# PIC32CK2051SG00144 device description
Architecture: CORTEX-M33; Family: PIC32CK; Series: PIC32CKSG00
Registers are 32-bit, read-write, reset 0x0 unless marked. A register's access mark holds for its fields unless they carry their own. Offsets are from the block's base; [hi:lo] are bit positions; {n}, {i} and the like mark numbered series; 'fields as' and 'values as' point back to an identical list.

## FUSES_BOOTCFG1 — Defines FUSE parameters
Instances: FUSES_BOOTCFG1 0x0A002000, FUSES_BOOTCFG2 0x0A00A000
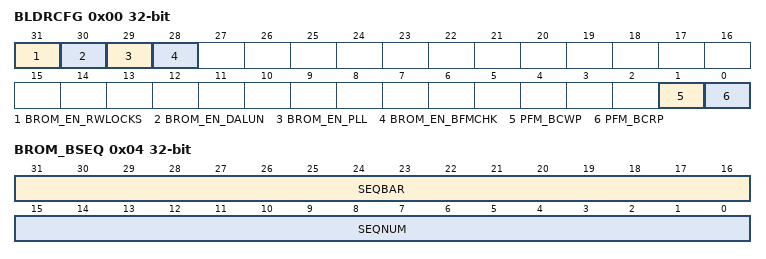
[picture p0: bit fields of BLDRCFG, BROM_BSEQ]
0x00 BLDRCFG reset not defined — Bootloader Configuration
  [31] BROM_EN_RWLOCKS — Enable Read/Write Locks
  [30] BROM_EN_DALUN — Enable DAL Unlock
  [29] BROM_EN_PLL — Enable PLL (Settings in PLL0_<REGS> are used)
  [28] BROM_EN_BFMCHK — Enable BFM CRC Check
    0=NONE (No verification); 1=CRC32 (Verify using crc32)
  [1] PFM_BCWP — Boot Configration Page Write Protect
  [0] PFM_BCRP — Boot Configration Page Read Protect
0x04 BROM_BSEQ reset not defined — Boot Configuraiton Page Sequence Number
  [31:16] SEQBAR — Sequence Number Bar (Negeated)
  [15:0] SEQNUM — Sequence Number
0x08 BFM_CHK_TABLEPTR reset not defined — BFM CRC Table Pointer
{0x20+4i} KEYVAL_TZ1_CE_NS[{i}] (i=0..3) reset not defined — Chip Erase Key for TZ1_NS
{0x30+4i} CELOCK_TZ1_CE_NS[{i}] (i=0..3) reset not defined — Chip Erase Lock for TZ1_NS
{0x40+4i} KEYVAL_TZ1_CE_S[{i}] (i=0..3) reset not defined — Chip Erase Key for TZ1_S
{0x50+4i} CELOCK_TZ1_CE_S[{i}] (i=0..3) reset not defined — Chip Erase Lock for TZ1_S
{0x60+4i} KEYVAL_TZ1_CE_ALL[{i}] (i=0..3) reset not defined — Chip Erase Key for TZ1_ALL
{0x70+4i} CELOCK_TZ1_CE_ALL[{i}] (i=0..3) reset not defined — Chip Erase Lock for TZ1_ALL
{0x80+4i} KEYVAL_TZ0_CE_ALL[{i}] (i=0..3) reset not defined — Chip Erase Key for TZ0_ALL
{0x90+4i} CELOCK_TZ0_CE_ALL[{i}] (i=0..3) reset not defined — Chip Erase Lock for TZ0_ALL
{0xA0+4i} KEYVAL_CRCCMD[{i}] (i=0..3) reset not defined — CRC Access Key
{0xB0+4i} KEYCONFIG_CRCCMD[{i}] (i=0..3) reset not defined — CRC Access Key Configuration
{0xC0+4i} KEYVAL_HOSTDALELEV[{i}] (i=0..3) reset not defined — Host Authenticated DAL Elevation Key
{0xD0+4i} KEYCONFIG_HOSTDALELEV[{i}] (i=0..3) reset not defined — Host Authenticated DAL Elevation Key Configuration
0xE0 ROM_CTRLA reset not defined — ROM CTRLA Settings (BROM_PLLEN must be set)
0xE4 FCR_CTRLA reset not defined — FCR CTRLA Settings (BROM_PLLEN must be set)
0xE8 RPMU_VREGCTRL reset not defined — RPMU VREGCTRL Settings (BROM_PLLEN must be set)
0xEC PLL0_CTRL reset not defined — PLL0 CTRL Settings (BROM_PLLEN must be set)
0xF0 PLL0_FBDIV reset not defined — PLL0 FBDIV Settings (BROM_PLLEN must be set)
0xF4 PLL0_REFDIV reset not defined — PLL0 REFDIV Settings (BROM_PLLEN must be set)
0xF8 PLL0_POSTDIVA reset not defined — PLL0 POSTDIVA Settings (BROM_PLLEN must be set)
0xFC MCLK_CLKDIV1 reset not defined — MCLK CLKDIV1 Settings (BROM_PLLEN must be set)
0x100 GCLK_GENCTRL0 reset not defined — GCLK GENCTRL0 Settings (BROM_PLLEN must be set)
{0x110+4i} BROM_BOOTCFGCRC[{i}] (i=0..3) reset not defined — Boot Configuraiton Page CRC
0x120 BROM_PAGEEND reset not defined — Page End Marker for Verified Data

## FUSES_DALCFG — Defines FUSE parameters
Instances: FUSES_DALCFG 0x0A004000
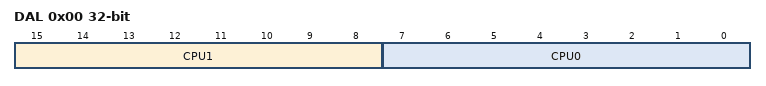
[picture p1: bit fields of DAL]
0x00 DAL — Debug Access Level
  [15:8] CPU1 — HSM DAL Elevation Value
    129=DAL0 (FCW_DAL0_VALUE); 153=DAL1 (FCW_DAL1_VALUE); 219=DAL2 (FCW_DAL2_VALUE)
  [7:0] CPU0 — Host DAL Elevation Value
    values as CPU1

## FUSES_USERCFG1 — Defines FUSE parameters
Instances: FUSES_USERCFG1 0x0A000000, FUSES_USERCFG2 0x0A008000
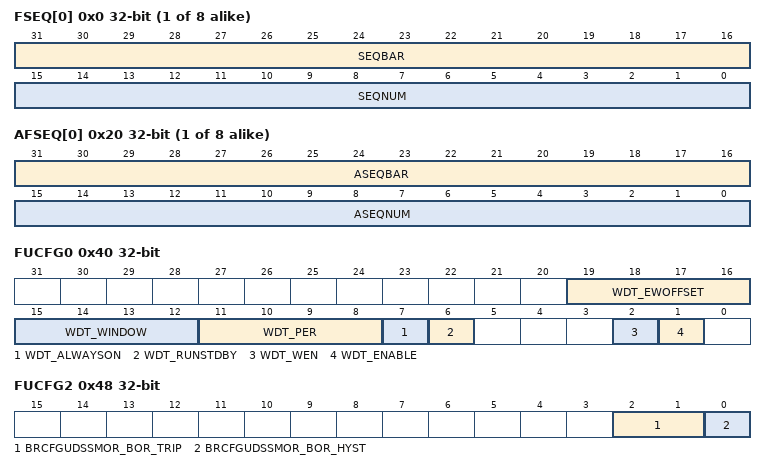
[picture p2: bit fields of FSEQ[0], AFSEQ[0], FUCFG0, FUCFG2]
{0x0+4i} FSEQ[{i}] (i=0..7) reset not defined — Flash Sequence Number
  [31:16] SEQBAR — Sequence Number Bar (Negeated)
  [15:0] SEQNUM — Sequence Number
{0x20+4i} AFSEQ[{i}] (i=0..7) reset not defined — Alternate Flash Sequence Number
  [31:16] ASEQBAR — Alternate Sequence Number Bar (Negeated)
  [15:0] ASEQNUM — Alternate Sequence Number
0x40 FUCFG0 reset not defined — WDT Configuration
  [19:16] WDT_EWOFFSET — Early Warning Interrupt Time Offset
  [15:12] WDT_WINDOW — Window Mode Time-out Period
  [11:8] WDT_PER — Time-out Period
  [7] WDT_ALWAYSON — Always On
  [6] WDT_RUNSTDBY — Run in Standby
  [2] WDT_WEN — Window Mode Enable
  [1] WDT_ENABLE — Enable
0x44 FUCFG1 reset not defined — User Configuration 1 (System Bus Configuration)
0x48 FUCFG2 reset not defined — User Configuration 2 (Deep Sleep SMOR Configuration)
  [2:1] BRCFGUDSSMOR_BOR_TRIP — BOT Trip Points
  [0] BRCFGUDSSMOR_BOR_HYST — BOT Trip Hystersis
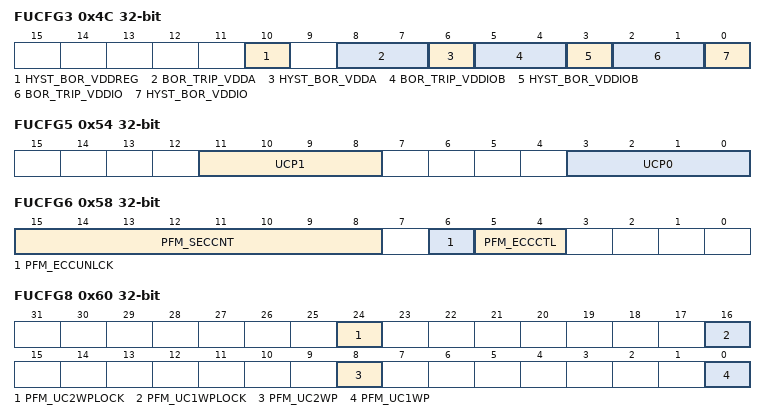
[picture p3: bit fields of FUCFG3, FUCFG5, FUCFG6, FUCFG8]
0x4C FUCFG3 reset not defined — User Configuration 2 (SMOR Configuration)
  [10] HYST_BOR_VDDREG — BOR Trip Point Hystersis for VDDREG
  [8:7] BOR_TRIP_VDDA — BOR Trip Points for VDDANA
  [6] HYST_BOR_VDDA — BOR Trip Point Hystersis for VDDANA
  [5:4] BOR_TRIP_VDDIOB — BOR Trip Points for VDDIOB
  [3] HYST_BOR_VDDIOB — BOR Trip Point Hystersis for VDDIOB
  [2:1] BOR_TRIP_VDDIO — BOR Trip Points for VDDIO
  [0] HYST_BOR_VDDIO — BOR Trip Point Hystersis for VDDIO
0x54 FUCFG5 — User Configuration 5 (VREG Charge Pump Configuration)
  [11:8] UCP1 — User charge pump setting
  [3:0] UCP0 — User charge pump setting
0x58 FUCFG6 reset not defined — User Configuration 6 (FCR ECCCTRL Configuration)
  [15:8] PFM_SECCNT — Flash SEC Count
  [6] PFM_ECCUNLCK — ECC Mode Control Unlock
  [5:4] PFM_ECCCTL — ECC Mode Control
0x5C FUCFG7 reset not defined — User Configuration 7 (FCR CTRLB Configuration)
  [1] PFM_TEMP — NVM Operating Temperature Read Mode
0x60 FUCFG8 reset not defined — User Configuration 8 (FCW CWP Configuration)
  [24] PFM_UC2WPLOCK — User Configuration Page 2 Write Protection Lock
  [16] PFM_UC1WPLOCK — User Configuration Page 1 Write Protection Lock
  [8] PFM_UC2WP — User Configuration Page 2 Write Protect
  [0] PFM_UC1WP — User Configuration Page 1 Write Protect
0x64 FUCFG9 reset not defined — User Configuration 9 (RAM BISR and ECC Configuraiton)
0x68 FUCFG10 reset not defined — IDAU_NONSECA
  [31:0] BOOTROM_NONSECA
0x6C FUCFG11 reset not defined — IDAU_NONSECB
  [31:0] BOOTROM_NONSECB
0x70 FUCFG12 reset not defined — IDAU_NONSECC
  [31:0] BOOTROM_NONSECC
0x74 FUCFG13 reset not defined — IDAU_NONSECAHB
  [31:0] BOOTROM_NONSECAHB
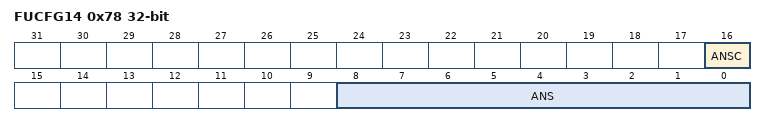
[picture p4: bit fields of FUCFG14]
0x78 FUCFG14 reset not defined — PFM IDAU Configuration
  [16] ANSC — Non-secure callable Flash application size
  [8:0] ANS — Non-secure Flash application size
0x7C FUCFG15 reset not defined — RAM IDAU Configuration
  [6:0] RNS — Non-secure RAM size
0x80 FUCFG16 reset not defined — User Configuration 16 (HSM Firmware Metadata 0 Address)
  [31:0] HSM_PTRMETA0 — HSM Firmware Metadata pointer 0
0xA0 FUCFG24 reset not defined — User Configuration 24 (HSM Firmware Metadata 1 Address)
  [31:0] HSM_PTRMETA1 — HSM Firmware Metadata pointer 1

## Notices in the file
Copyright (c) 2021 Microchip Technology Inc.
SPDX-License-Identifier: Apache-2.0
Licensed under the Apache License, Version 2.0 (the "License");
you may not use this file except in compliance with the License.
You may obtain a copy of the License at
http://www.apache.org/licenses/LICENSE-2.0
Unless required by applicable law or agreed to in writing, software
distributed under the License is distributed on an "AS IS" BASIS,
WITHOUT WARRANTIES OR CONDITIONS OF ANY KIND, either express or implied.
See the License for the specific language governing permissions and
limitations under the License.
